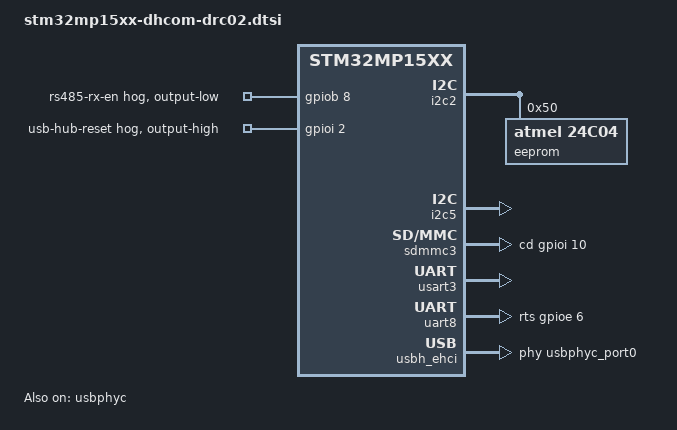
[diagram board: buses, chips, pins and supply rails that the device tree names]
#include <dt-bindings/input/input.h>
#include <dt-bindings/pwm/pwm.h>
/ {
	aliases {
		serial0 = &uart4;
		serial1 = &usart3;
		serial2 = &uart8;
	};
	chosen {
		stdout-path = "serial0:115200n8";
	};
};
&adc {
	status = "disabled";
};
&dac {
	status = "disabled";
};
&gpiob {
	rs485-rx-en-hog {
		gpio-hog;
		gpios = <8 0>;
		output-low;
		line-name = "rs485-rx-en";
	};
};
&gpiod {
	gpio-line-names = "", "", "", "",
			  "", "", "DHCOM-B", "",
			  "", "", "", "DRC02-Out1",
			  "DRC02-Out2", "", "", "";
};
&gpioi {
	gpio-line-names = "DRC02-In1", "DHCOM-O", "DHCOM-H", "DHCOM-I",
			  "DHCOM-R", "DHCOM-M", "", "",
			  "DRC02-In2", "", "", "",
			  "", "", "", "";
	usb-hub-hog {
		gpio-hog;
		gpios = <2 0>;
		output-high;
		line-name = "usb-hub-reset";
	};
};
&i2c2 {
	pinctrl-names = "default";
	pinctrl-0 = <&i2c2_pins_a>;
	i2c-scl-rising-time-ns = <185>;
	i2c-scl-falling-time-ns = <20>;
	status = "okay";
	/delete-property/dmas;
	/delete-property/dma-names;
	status = "okay";
	eeprom@50 {
		compatible = "atmel,24c04";
		reg = <0x50>;
		pagesize = <16>;
	};
};
&i2c4 {
	touchscreen@49 {
		status = "disabled";
	};
};
&i2c5 {	 
	pinctrl-names = "default";
	pinctrl-0 = <&i2c5_pins_a>;
	i2c-scl-rising-time-ns = <185>;
	i2c-scl-falling-time-ns = <20>;
	status = "okay";
	/delete-property/dmas;
	/delete-property/dma-names;
};
&sdmmc3 {
	/delete-property/broken-cd;
	cd-gpios = <&gpioi 10 GPIO_ACTIVE_HIGH>;
	disable-wp;
};
&spi1 {
	pinctrl-names = "default";
	pinctrl-0 = <&spi1_pins_a>;
	cs-gpios = <&gpioz 3 0>;
	/delete-property/dmas;
	/delete-property/dma-names;
	status = "disabled";	 
};
&usart3 {
	pinctrl-names = "default";
	pinctrl-0 = <&usart3_pins_a>;
	/delete-property/dmas;
	/delete-property/dma-names;
	status = "okay";
};
&uart8 {	 
	linux,rs485-enabled-at-boot-time;
	pinctrl-names = "default";
	pinctrl-0 = <&uart8_pins_a>;
	rts-gpios = <&gpioe 6 GPIO_ACTIVE_HIGH>;
	/delete-property/dmas;
	/delete-property/dma-names;
	status = "okay";
};
&usbh_ehci {
	phys = <&usbphyc_port0>;
	status = "okay";
};
&usbphyc {
	status = "okay";
};
&usbphyc_port0 {
	phy-supply = <&vdd_usb>;
};
&usbphyc_port1 {
	phy-supply = <&vdd_usb>;
};
